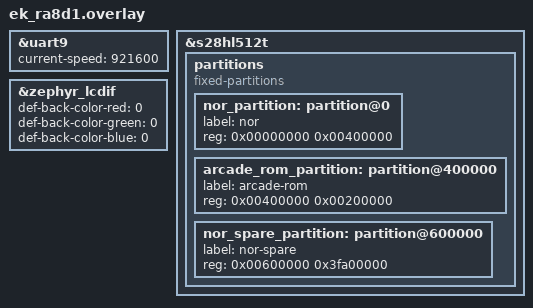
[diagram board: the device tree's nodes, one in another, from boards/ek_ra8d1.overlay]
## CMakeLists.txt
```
cmake_minimum_required(VERSION 3.20.0)
find_package(Zephyr REQUIRED HINTS $ENV{ZEPHYR_BASE})
project(ra8d1_arcade)

# emu/ is portable C99 and knows nothing about Zephyr or this board. It is
# compiled unchanged by host/Makefile for the test harnesses.
target_sources(app PRIVATE
	emu/z80.c
	emu/pacman.c
	emu/romimage.c
)

# src/ is the platform shim plus glue. platform_zephyr.c is the only file
# that knows what board this is, and it takes its facts from devicetree.
target_sources(app PRIVATE
	src/main.c
	src/platform_zephyr.c
)

# The display stage owns video.c. It builds in only once a board actually has
# a panel configured, so the two stages can land independently.
#
# Gate on a chosen zephyr,display rather than on CONFIG_DISPLAY. They are not
# the same condition: CONFIG_DISPLAY only says the display subsystem is
# compiled in, and it can be enabled on a board with no panel wired - for
# ek_ra8d1 the panel arrives with SHIELD=rtkmipilcdb00000be, not with the
# board. Gating on the Kconfig symbol makes a shieldless build fail at
# video.c's BUILD_ASSERT instead of quietly building headless.
#
# ARCADE_HAS_DISPLAY carries the same condition into C. main.c uses that
# rather than testing devicetree itself, so it keeps its rule of including no
# Zephyr headers.
dt_chosen(arcade_display_node PROPERTY "zephyr,display")
if(DEFINED arcade_display_node)
	target_sources(app PRIVATE src/video.c)
	target_compile_definitions(app PRIVATE ARCADE_HAS_DISPLAY)
endif()

target_include_directories(app PRIVATE src emu)
```

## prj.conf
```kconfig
# Native Z80 arcade emulator - board-neutral configuration.
#
# Everything here is true of the app on any Zephyr board. Board-specific
# symbols live in boards/<board>.conf, which Zephyr merges on top of this
# file. If you find yourself adding a symbol here whose name contains a
# vendor or a part number, it belongs in the board file instead.

CONFIG_PRINTK=y
CONFIG_BOOT_BANNER=n
CONFIG_MAIN_STACK_SIZE=8192

# The ROM image lives in a flash partition labelled "arcade-rom", declared by
# the board overlay. Which flash, and where, is the board's business.
CONFIG_FLASH=y

# Display output. The app runs headless without this - src/main.c only
# references video.h under CONFIG_DISPLAY - so the display stage can be
# built and landed independently of the emulator.
CONFIG_DISPLAY=y

# The emulator state is ~118 KB of .bss and we want it in internal SRAM, not
# SDRAM: the Z80's whole address space is 20 KB and keeping it on-chip is the
# single biggest win available to the interpreter.
CONFIG_SPEED_OPTIMIZATIONS=y
CONFIG_CRC=y
```

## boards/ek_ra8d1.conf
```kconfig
# EK-RA8D1 specific Kconfig for the arcade app.
#
# Merged on top of prj.conf (Zephyr appends prj.conf, then socs/, then
# boards/ - see cmake/modules/configuration_files.cmake). Only symbols that
# are true of THIS board belong here; anything the app needs on every board
# belongs in prj.conf.

# SDRAM controller. The board DTS marks &sdram okay but the memc driver class
# still has to be enabled, and on this board nothing enables it for us. Other
# boards do: stm32f746g_disco's Kconfig.defconfig has
# "config MEMC / default y if STM32_LTDC", because its display controller
# needs it. That is the board doing its own job, which is why this line is
# here rather than in prj.conf.
CONFIG_MEMC=y

# MIPI-DSI host and the GLCDC. Both are `default y` on their devicetree
# dependency once SHIELD=rtkmipilcdb00000be is applied, so these are
# belt-and-braces rather than load-bearing.
CONFIG_MIPI_DSI=y
CONFIG_RENESAS_RA_GLCDC=y

# One GLCDC framebuffer rather than the default two.
#
# For this app it is purely a memory saving: every hazard in the two-buffer
# path lives inside ra_display_write(), and src/video.c never calls it - it
# drives the GLCDC through FSP directly. At the default of 2 we would just
# reserve a second 819,840-byte buffer in SDRAM that nothing ever touches.
#
# Do NOT set this to 0. At 0 the driver's framebuffer becomes a zero-length
# array while display_get_framebuffer() still returns a non-NULL pointer into
# it, and plat_video_init() memsets 819,840 bytes through that pointer.
CONFIG_RENESAS_RA_GLCDC_FB_NUM=1

# The GT911 touch controller on the MIPI shield shares the DSI reset line
# with the panel, so the panel does not come up without I2C available.
CONFIG_I2C=y

# D-cache is a 3.8x swing on SDRAM reads on this board (123 vs 32 MiB/s), and
# the GLCDC scans out of SDRAM as a bus master that does not see the cache,
# so cache maintenance has to be available for video.c to flush against.
CONFIG_ICACHE=y
CONFIG_DCACHE=y
CONFIG_CACHE_MANAGEMENT=y
```

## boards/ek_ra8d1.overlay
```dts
/*
 * EK-RA8D1 wiring for the arcade app.
 *
 * Everything in this file is specific to this board: node labels like
 * `uart9`, `s28hl512t` and `zephyr_lcdif` exist on the EK-RA8D1 and nowhere
 * else. Porting to another Zephyr board means writing a sibling file here,
 * `boards/<board>.overlay`, and changing no source.
 *
 * Note there is deliberately no `app.overlay`. Zephyr picks the application
 * devicetree overlay by a fallback chain, not a merge (see
 * cmake/modules/configuration_files.cmake): once `boards/<board>.overlay`
 * exists it is used and `app.overlay` is never read. Keeping both would mean
 * the second one silently does nothing. Genuinely board-neutral devicetree,
 * if we ever have any, belongs in a `.dtsi` included from each board file.
 *
 * Kconfig is the other way round: `prj.conf` and `boards/<board>.conf` are
 * merged, so the board-specific Kconfig lives in the sibling `.conf`.
 */

/* Console at 921600 rather than 115200. Pushing a ROM image is only ~25 KB
 * for Pac-Man so the baud hardly matters here, but the rvlinux app on this
 * board already runs its console at this rate and the J-Link OB VCOM handles
 * it, so one terminal setting works for both. */
&uart9 {
	current-speed = <921600>;
};

/*
 * Carve a ROM slot out of the octo-SPI NOR.
 *
 * The board DTS declares a single "nor" partition covering all 64 MB. Split
 * it so the arcade ROM has a named home the app can find by label, instead
 * of a hardcoded 0x400000 in C.
 *
 * The layout below matches what is already on this part: 0x0-0x1FFFF is the
 * CIRCUITPY filesystem and 0x2000 is the OSPI driver's autocalibration
 * sector, and the emulated-Linux image sits from 0x40000 and runs to a few
 * MB. The arcade slot starts at 4 MB, clear of all of it, and is 2 MB, which
 * is ample: a full Pac-Man image is ~25 KB.
 */
&s28hl512t {
	/delete-node/ partitions;

	partitions {
		compatible = "fixed-partitions";
		#address-cells = <1>;
		#size-cells = <1>;

		/* Everything the other apps on this board already use. */
		nor_partition: partition@0 {
			label = "nor";
			reg = <0x00000000 0x00400000>;
		};

		arcade_rom_partition: partition@400000 {
			label = "arcade-rom";
			reg = <0x00400000 0x00200000>;
		};

		/* The rest of the 64 MB part, unclaimed. */
		nor_spare_partition: partition@600000 {
			label = "nor-spare";
			reg = <0x00600000 0x3fa00000>;
		};
	};
};

/*
 * Black the letterbox.
 *
 * The arcade raster is 224x288 and the panel is 480x854, so the scaled image
 * never fills the screen and the GLCDC paints the surround with its default
 * background colour. The driver defaults every channel to 255
 * (display_renesas_ra.h, DT_INST_PROP_OR(n, def_back_color_*, 255)), so
 * without this the border comes up white.
 *
 * `zephyr_lcdif` is labelled in ek_ra8d1.dts itself, not in the shield, so
 * this is safe to apply to a headless build too: the node is simply disabled
 * and these properties go nowhere.
 */
&zephyr_lcdif {
	def-back-color-red = <0>;
	def-back-color-green = <0>;
	def-back-color-blue = <0>;
};
```

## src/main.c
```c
/*
 * Namco Pac-Man arcade hardware, emulated natively on a Cortex-M85.
 *
 * This runs directly on the MCU. It is deliberately NOT hosted inside the
 * emulated RISC-V Linux that also lives on the EK-RA8D1: nesting an M85
 * emulating a RISC-V emulating a Z80 compounds to well over a thousand host
 * cycles per Z80 instruction, roughly ten times too slow for Pac-Man's
 * 3.072 MHz. Emulating the Z80 directly costs tens of cycles.
 *
 * Layering, which is the point of how this file is written:
 *
 *   emu/       portable C99, no Zephyr, no board. Compiles on the Mac for
 *              the test harnesses and on the target unchanged.
 *   src/platform.h, video.h
 *              the thin shim: ROM storage, timing, input, framebuffer.
 *   src/platform_zephyr.c, video.c
 *              the only files that know the board, and they take their facts
 *              from devicetree rather than from constants.
 *   src/main.c this file. Glue only: no addresses, no panel size, no flash
 *              offsets, no driver includes.
 *
 * ROMs: none are shipped. Push an image built by tools/mkromimage.py (your
 * own dump) or tools/mktestrom.py (synthetic, no arcade ROM involved) with
 * tools/pushrom.py. It persists across resets and app reflashes.
 */

/* No Zephyr headers here on purpose: this file is glue, and everything it
 * needs from the system comes through platform.h and video.h. That keeps it
 * compilable against any implementation of the shim. */
#include <stdbool.h>
#include <stddef.h>
#include <stdint.h>
#include <string.h>

#include "pacman.h"
#include "romimage.h"
#include "platform.h"

/* The display stage owns video.h/video.c. Until the board has a panel - a
 * chosen zephyr,display, which CMakeLists turns into ARCADE_HAS_DISPLAY -
 * this app runs headless and never references it, so the two stages can land
 * independently. */
#if defined(ARCADE_HAS_DISPLAY)
#include "video.h"
#endif

/* ------------------------------------------------------------------- state */

/* ~118 KB. Lives in .bss, i.e. internal SRAM: the Z80's whole address space
 * is 20 KB and the decoded graphics are 32 KB, so the emulator's hot working
 * set stays on-chip and never touches external memory. That is the single
 * biggest performance decision in the project. */
static pacman_t machine;

/* ------------------------------------------------------------- console fmt */

static void us(const char *s)
{
	plat_puts(s);
}

static void udec(uint32_t v)
{
	char b[12];
	int n = 0;

	if (v == 0) {
		plat_putc('0');
		return;
	}
	while (v) {
		b[n++] = (char) ('0' + v % 10);
		v /= 10;
	}
	while (n--) {
		plat_putc(b[n]);
	}
}

/* Fixed-point decimal with two places, for rates and multiples. */
static void udec2(uint32_t whole, uint32_t hundredths)
{
	udec(whole);
	plat_putc('.');
	plat_putc((char) ('0' + (hundredths / 10) % 10));
	plat_putc((char) ('0' + hundredths % 10));
}

/* ----------------------------------------------------------------- rom load */

static bool rom_present(romimg_t *img)
{
	size_t slot;
	const uint8_t *base = plat_rom_base(&slot);

	if (base == NULL) {
		us("rom: no ROM storage on this platform\r\n");
		return false;
	}

	romimg_err_t e = romimg_parse(base, slot, true, img);

	if (e == ROMIMG_OK) {
		e = romimg_check_pacman(img);
	}
	if (e != ROMIMG_OK) {
		us("rom: ");
		us(romimg_strerror(e));
		us("\r\n");
		return false;
	}

	us("rom: ok, ");
	udec(img->total_len);
	us(" bytes");
	if (img->flags & ROMIMG_FLAG_SYNTHETIC) {
		us(" (synthetic test image)");
	}
	us("\r\n");
	return true;
}

/*
 * Receive a ROM image over the console and hand it to the platform.
 *
 * The container carries its own length and CRC, so the wire protocol is just
 * 'S', a 4-byte little-endian length, then the bytes. Erase granularity,
 * write-block size and the hold-back of the header block are all the
 * platform's problem, not this function's.
 */
static int rom_receive(void)
{
	uint32_t len = 0;
	int c;

	us("\r\nLOADER: send 'S' then <len:4 LE> then the image\r\n");

	do {
		c = plat_getc_timeout(3600u * 1000u);
		if (c < 0) {
			us("LOADER: timeout\r\n");
			return -1;
		}
	} while (c != 'S');

	for (int i = 0; i < 4; i++) {
		c = plat_getc_timeout(5000u);
		if (c < 0) {
			return -1;
		}
		len |= (uint32_t) c << (8 * i);
	}

	us("LOADER: len=");
	udec(len);
	us(", erasing\r\n");

	if (plat_rom_write_begin(len) != 0) {
		us("LOADER: cannot open ROM slot\r\n");
		return -1;
	}

	/* The erase is long enough that anything sent meanwhile is already lost
	 * in the FIFO. Drain, then say explicitly when ready. */
	while (plat_getc() >= 0) {
		/* drain */
	}
	us("\r\n<RDY>\r\n");

	for (uint32_t off = 0; off < len; off++) {
		uint8_t byte;

		c = plat_getc_timeout(10000u);
		if (c < 0) {
			us("LOADER: rx timeout at ");
			udec(off);
			us("\r\n");
			return -1;
		}
		byte = (uint8_t) c;

		if (plat_rom_write(&byte, 1) != 0) {
			us("LOADER: write failed at ");
			udec(off);
			us("\r\n");
			return -1;
		}
		if ((off & 0xFFF) == 0) {
			plat_putc('.');
		}
	}

	if (plat_rom_write_end() != 0) {
		us("\r\nLOADER: commit failed\r\n");
		return -1;
	}

	us("\r\nLOADER: done\r\n");
	return 0;
}

/* --------------------------------------------------------------- benchmark */

/*
 * How much faster than real time can this board run the machine?
 *
 * CPU and render only. The cost of getting pixels onto the panel is measured
 * by the video layer, which is where the scaling strategy lives; see
 * notes/02-video.md. Duplicating a blit here would only produce a second,
 * stale number for the same thing.
 */
static void benchmark(void)
{
	const int warm = 30;
	const int n = 300;

	machine.watchdog_enable = false;    /* a reset mid-run skews the counts */

	for (int i = 0; i < warm; i++) {
		pacman_run_frame(&machine);
	}

	uint64_t i0 = machine.instrs;
	unsigned long c0 = machine.cpu.cyc;

	uint64_t t0 = plat_now_us();

	for (int i = 0; i < n; i++) {
		pacman_run_frame(&machine);
	}
	uint64_t t_full = plat_now_us() - t0;

	uint64_t instrs = machine.instrs - i0;
	uint32_t tstates = (uint32_t) (machine.cpu.cyc - c0);

	t0 = plat_now_us();
	for (int i = 0; i < n; i++) {
		pacman_render(&machine);
	}
	uint64_t t_render = plat_now_us() - t0;

	uint64_t t_cpu = (t_full > t_render) ? (t_full - t_render) : 1;

	us("\r\n--- benchmark over ");
	udec(n);
	us(" frames ---\r\n");

	us("z80 instructions   ");
	udec((uint32_t) instrs);
	us("  (");
	udec((uint32_t) (instrs / n));
	us(" per frame)\r\n");

	us("t-states per instr ");
	udec2(tstates / (uint32_t) instrs,
	      (uint32_t) ((uint64_t) tstates * 100 / instrs) % 100);
	us("\r\n");

	us("cpu emulation      ");
	udec((uint32_t) (t_cpu / n));
	us(" us/frame, ");
	udec((uint32_t) (instrs * 1000000u / t_cpu / 1000u));
	us(" K z80-instr/s\r\n");

	us("render 224x288     ");
	udec((uint32_t) (t_render / n));
	us(" us/frame\r\n");

	uint32_t us_frame = (uint32_t) (t_full / n);
	uint32_t us_budget = 1000000u / 61u;

	us("emulation total    ");
	udec(us_frame);
	us(" us of a ");
	udec(us_budget);
	us(" us frame budget\r\n");

	if (us_frame) {
		uint32_t x100 = us_budget * 100u / us_frame;

		us("real-time multiple ");
		udec2(x100 / 100, x100 % 100);
		us("x  (emulation only, display not included)\r\n");
	}

	machine.watchdog_enable = true;
	pacman_reset(&machine);
}

/* -------------------------------------------------------------------- main */

/* Map the platform's abstract buttons onto this machine's cabinet. Which
 * physical control produces which bit is the platform's business; which
 * cabinet input it drives is this machine's. */
static void apply_input(uint32_t btns)
{
	static const struct {
		uint32_t bit;
		pacman_btn_t btn;
	} map[] = {
		{ PLAT_BTN_UP,     PACMAN_BTN_UP },
		{ PLAT_BTN_DOWN,   PACMAN_BTN_DOWN },
		{ PLAT_BTN_LEFT,   PACMAN_BTN_LEFT },
		{ PLAT_BTN_RIGHT,  PACMAN_BTN_RIGHT },
		{ PLAT_BTN_COIN,   PACMAN_BTN_COIN1 },
		{ PLAT_BTN_START1, PACMAN_BTN_START1 },
		{ PLAT_BTN_START2, PACMAN_BTN_START2 },
	};

	for (unsigned i = 0; i < sizeof(map) / sizeof(map[0]); i++) {
		pacman_set_input(&machine, map[i].btn,
				 (btns & map[i].bit) != 0);
	}
}

int main(void)
{
	us("\r\n\r\nra8d1-arcade: pac-man, native on cortex-m85\r\n");

	romimg_t img;

	if (!rom_present(&img)) {
		us("\r\nNo usable ROM image in flash.\r\n");
		us("Build one with tools/mktestrom.py (synthetic, no arcade\r\n");
		us("ROM needed) or tools/mkromimage.py (your own dump), then\r\n");
		us("push it with tools/pushrom.py.\r\n");

		if (rom_receive() != 0 || !rom_present(&img)) {
			us("no valid image; halting\r\n");
			return 0;
		}
	}

	if (!pacman_load(&machine, img.cpu, img.gfx, img.prom)) {
		us("pacman_load failed\r\n");
		return 0;
	}
	us("machine loaded, state ");
	udec((uint32_t) sizeof(machine) / 1024);
	us(" KB in internal SRAM\r\n");

	/*
	 * Draw straight into the platform's framebuffer when there is one.
	 * pacman_render() writes PACMAN_W x PACMAN_H bytes of palette index at
	 * whatever stride it is given, so this costs nothing and saves a 64 KB
	 * copy per frame. Without a display the machine keeps its own buffer
	 * and everything still runs.
	 */
	bool have_display = false;

#if defined(ARCADE_HAS_DISPLAY)
	if (plat_video_init(PACMAN_W, PACMAN_H) == 0) {
		uint32_t pal[32];

		pacman_set_surface(&machine, plat_get_framebuffer(),
				   plat_fb_stride());
		pacman_palette_rgb888(&machine, pal);
		plat_set_palette(pal, 0, 32);
		have_display = true;

		us("display ");
		udec(plat_fb_width() * plat_scale());
		plat_putc('x');
		udec(plat_fb_height() * plat_scale());
		us(" at ");
		udec(plat_scale());
		us("x scale\r\n");
	} else {
		us("display init failed; running headless\r\n");
	}
#else
	us("no display configured; running headless\r\n");
#endif

	benchmark();

	us("\r\nfree-running at 60.6 Hz\r\n");

	const uint64_t frame_us = 1000000u / 61u;
	uint64_t next = plat_now_us();

	for (;;) {
		apply_input(plat_poll_input());

		if (have_display) {
#if defined(ARCADE_HAS_DISPLAY)
			plat_wait_vsync();
#endif
		}

		pacman_run_frame(&machine);

		if (have_display) {
#if defined(ARCADE_HAS_DISPLAY)
			plat_present();
#endif
		}

		next += frame_us;
		plat_sleep_until_us(next);

		if (machine.frame % 303 == 0) {
			us("frame ");
			udec(machine.frame);
			us("\r\n");
		}
	}

	return 0;
}
```

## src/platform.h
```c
/*
 * platform.h - everything board-specific that is not video.
 *
 * Portable by construction: stdint/stdbool/stddef only, no Zephyr, no FSP, no
 * devicetree, no board constants. The app and the machine layer include this
 * to reach the hardware; the implementation is the only file allowed to know
 * what board it is on.
 *
 * Video deliberately lives in its own header, video.h, because the display
 * contract is larger and has its own lifecycle. The split is:
 *
 *   video.h     framebuffer, palette, scaling, vsync, present
 *   platform.h  ROM storage, wall clock, input
 *
 * A port to another Zephyr board should need a new implementation file and a
 * devicetree, and no change above this line.
 */
#ifndef ARCADE_PLATFORM_H_
#define ARCADE_PLATFORM_H_

#include <stdbool.h>
#include <stddef.h>
#include <stdint.h>

/* --------------------------------------------------------------- rom store */

/*
 * The ROM image, as a directly readable pointer.
 *
 * Platforms with memory-mapped flash return a pointer into that window and
 * the image is parsed and decoded in place, with no copy. Platforms without
 * it are free to read the image into RAM and return that instead; callers
 * cannot tell the difference and must not assume either.
 *
 * Returns NULL if the platform has no ROM storage at all. `size` is set to
 * the number of bytes readable from the returned pointer, which is the size
 * of the slot, not of the image; the container header carries the real
 * length.
 */
const uint8_t *plat_rom_base(size_t *size);

/*
 * Commit `len` bytes to the ROM slot, replacing whatever was there.
 *
 * Split into begin/write/end because erase granularity, write-block size and
 * alignment are all platform properties: some parts refuse writes that are
 * not whole aligned blocks. The implementation buffers as needed, so callers
 * may pass any chunk size.
 *
 * Returns 0 or a negative errno. Not all platforms implement this; -ENOTSUP
 * from plat_rom_write_begin() means "no writable ROM slot here".
 */
int plat_rom_write_begin(size_t len);
int plat_rom_write(const uint8_t *data, size_t len);
int plat_rom_write_end(void);

/* ------------------------------------------------------------------ timing */

/* Monotonic microseconds since boot. Must be cheap: the frame loop and the
 * benchmark both call it. */
uint64_t plat_now_us(void);

/* Busy-wait until plat_now_us() reaches `deadline_us`. */
void plat_sleep_until_us(uint64_t deadline_us);

/* ------------------------------------------------------------------- input */

/*
 * Abstract cabinet controls, active high (pressed = 1). The machine layer
 * maps these onto whatever its board's input ports look like; the platform
 * maps them from whatever the hardware has - GPIO, USB HID, a UART key, or
 * nothing at all.
 */
enum {
	PLAT_BTN_UP     = 1u << 0,
	PLAT_BTN_DOWN   = 1u << 1,
	PLAT_BTN_LEFT   = 1u << 2,
	PLAT_BTN_RIGHT  = 1u << 3,
	PLAT_BTN_FIRE   = 1u << 4,
	PLAT_BTN_COIN   = 1u << 5,
	PLAT_BTN_START1 = 1u << 6,
	PLAT_BTN_START2 = 1u << 7,
};

/* Current button state as a bitmask of PLAT_BTN_*. Returns 0 on a platform
 * with no input wired up, which is a valid configuration: the machine just
 * sees an idle cabinet. */
uint32_t plat_poll_input(void);

/* ----------------------------------------------------------------- console */

/* Byte-level console, used for diagnostics and the ROM loader. Kept here so
 * the app does not include a UART driver directly. */
void plat_putc(char c);
void plat_puts(const char *s);

/* Returns the next byte, or -1 if none is available. */
int plat_getc(void);

/* Blocks up to `timeout_ms` for a byte; -1 on timeout. */
int plat_getc_timeout(uint32_t timeout_ms);

#endif /* ARCADE_PLATFORM_H_ */
```

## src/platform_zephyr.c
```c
/*
 * platform_zephyr.c - the Zephyr implementation of src/platform.h.
 *
 * This is the ONLY file in the project that is allowed to know what board it
 * is running on, and even here the board facts come from devicetree rather
 * than from constants:
 *
 *   console        DT_CHOSEN(zephyr_console)
 *   ROM slot       the "arcade-rom" fixed-partition: device, offset and size
 *   XIP window     DT_REG_ADDR of the flash node the partition lives on
 *   erase/write    the flash driver's own page layout and write-block size
 *
 * Porting to another Zephyr board should mean writing a devicetree overlay
 * that declares an "arcade-rom" partition, not editing this file. If the
 * board's flash is not memory-mapped, plat_rom_base() falls back to reading
 * the image into RAM and callers cannot tell.
 */

#include <zephyr/kernel.h>
#include <zephyr/device.h>
#include <zephyr/devicetree.h>
#include <zephyr/drivers/uart.h>
#include <zephyr/drivers/flash.h>
#include <zephyr/storage/flash_map.h>
#include <zephyr/cache.h>
#include <zephyr/sys/util.h>
#include <string.h>
#include <errno.h>

#include "platform.h"

/* ------------------------------------------------------------------- board */

#define ROM_PARTITION       arcade_rom_partition

/* DT_MTD_FROM_FIXED_PARTITION walks partition -> partitions -> flash node,
 * so the device, its XIP window and the slot bounds all come from the same
 * devicetree entry and cannot drift apart. */
#define ROM_FLASH_NODE      DT_MTD_FROM_FIXED_PARTITION(DT_NODELABEL(ROM_PARTITION))
#define ROM_FLASH_DEV       DEVICE_DT_GET(ROM_FLASH_NODE)
#define ROM_OFFSET          DT_REG_ADDR(DT_NODELABEL(ROM_PARTITION))
#define ROM_SIZE            DT_REG_SIZE(DT_NODELABEL(ROM_PARTITION))

/* The flash node's own reg gives the memory-mapped (XIP) base and the part
 * size. On this board that is 0x90000000 and 64 MB, but taking it from the
 * node means a different part or a different chip select needs no edit. */
#define FLASH_XIP_BASE      DT_REG_ADDR(ROM_FLASH_NODE)

/* Largest erase block the part advertises, used to round the erase up. */
#define ROM_ERASE_SZ        (256U * 1024U)

/* Small flash_write() calls fail on this NOR, so writes are buffered into
 * whole aligned blocks. See ra8d1-linux/ra8d-bringup.md. */
#define ROM_WRITE_BLK       4096U

/*
 * Devicetree sanity, checked at build time so a bad overlay is a compile
 * error rather than a confusing runtime failure. These are invariants, not
 * addresses: asserting specific values here would just move the board
 * constants back into C, which is what the devicetree is for.
 */
BUILD_ASSERT(ROM_OFFSET % ROM_ERASE_SZ == 0,
	     "arcade-rom partition must start on an erase-block boundary");
BUILD_ASSERT(ROM_SIZE % ROM_ERASE_SZ == 0,
	     "arcade-rom partition must be a whole number of erase blocks");
BUILD_ASSERT(ROM_SIZE >= 64 * 1024,
	     "arcade-rom partition is too small to hold a ROM image");
BUILD_ASSERT(ROM_ERASE_SZ % ROM_WRITE_BLK == 0,
	     "write block must divide the erase block");

static const struct device *const console_dev =
	DEVICE_DT_GET(DT_CHOSEN(zephyr_console));
static const struct device *const rom_flash = ROM_FLASH_DEV;

/* ----------------------------------------------------------------- console */

void plat_putc(char c)
{
	uart_poll_out(console_dev, c);
}

void plat_puts(const char *s)
{
	while (*s) {
		uart_poll_out(console_dev, *s++);
	}
}

int plat_getc(void)
{
	unsigned char c;

	return (uart_poll_in(console_dev, &c) == 0) ? (int) c : -1;
}

int plat_getc_timeout(uint32_t timeout_ms)
{
	int64_t end = k_uptime_get() + timeout_ms;
	int c;

	do {
		c = plat_getc();
		if (c >= 0) {
			return c;
		}
		k_busy_wait(50);
	} while (k_uptime_get() < end);

	return -1;
}

/* ------------------------------------------------------------------ timing */

uint64_t plat_now_us(void)
{
	return (uint64_t) k_ticks_to_us_floor64(k_uptime_ticks());
}

void plat_sleep_until_us(uint64_t deadline_us)
{
	for (;;) {
		uint64_t now = plat_now_us();

		if (now >= deadline_us) {
			return;
		}
		/* Long waits go to the scheduler; the last stretch spins so the
		 * frame does not overshoot by a whole tick. */
		if (deadline_us - now > 2000) {
			k_sleep(K_USEC(deadline_us - now - 1000));
		} else {
			k_busy_wait(20);
		}
	}
}

/* ------------------------------------------------------------------- input */

/*
 * Nothing is wired up yet. The board's two user buttons are the obvious
 * first move, and USB HID after that; both belong here rather than in the
 * machine layer. Returning 0 is a valid configuration - the machine simply
 * sees an idle cabinet.
 */
uint32_t plat_poll_input(void)
{
	return 0;
}

/* ---------------------------------------------------------------- rom store */

const uint8_t *plat_rom_base(size_t *size)
{
	if (size) {
		*size = ROM_SIZE;
	}

	/* This part is memory-mapped, so hand back a pointer into the XIP
	 * window and let the emulator decode in place. The window is cacheable,
	 * so drop any lines that predate a write we may have just done. */
	const uint8_t *p = (const uint8_t *) (FLASH_XIP_BASE + ROM_OFFSET);

	sys_cache_data_invd_range((void *) p, ROM_SIZE);
	return p;
}

/* Write state. The block buffer exists because the NOR rejects partial
 * writes, and callers should not have to care. */
static uint8_t wr_blk[ROM_WRITE_BLK];
static uint8_t wr_first[ROM_WRITE_BLK];
static size_t wr_fill;      /* bytes buffered in wr_blk */
static size_t wr_off;       /* bytes committed so far */
static size_t wr_total;
static bool wr_have_first;
static bool wr_active;

int plat_rom_write_begin(size_t len)
{
	if (!device_is_ready(rom_flash)) {
		return -ENODEV;
	}
	if (len == 0 || len > ROM_SIZE) {
		return -EINVAL;
	}

	size_t need = ROUND_UP(len, ROM_ERASE_SZ);

	if (flash_erase(rom_flash, ROM_OFFSET, need) != 0) {
		return -EIO;
	}

	wr_fill = 0;
	wr_off = 0;
	wr_total = len;
	wr_have_first = false;
	wr_active = true;
	return 0;
}

/* Commit one full block. The very first block holds the container magic and
 * is held back until the end, so a transfer that dies halfway never leaves
 * something that parses as a valid image. */
static int commit_block(void)
{
	int rc = 0;

	if (wr_off == 0) {
		memcpy(wr_first, wr_blk, ROM_WRITE_BLK);
		wr_have_first = true;
	} else {
		rc = flash_write(rom_flash, ROM_OFFSET + wr_off, wr_blk,
				 ROM_WRITE_BLK);
	}

	wr_off += ROM_WRITE_BLK;
	wr_fill = 0;
	memset(wr_blk, 0xFF, sizeof(wr_blk));
	return rc ? -EIO : 0;
}

int plat_rom_write(const uint8_t *data, size_t len)
{
	if (!wr_active) {
		return -EINVAL;
	}

	while (len) {
		size_t n = MIN(len, ROM_WRITE_BLK - wr_fill);

		memcpy(wr_blk + wr_fill, data, n);
		wr_fill += n;
		data += n;
		len -= n;

		if (wr_fill == ROM_WRITE_BLK) {
			int rc = commit_block();

			if (rc) {
				wr_active = false;
				return rc;
			}
		}
	}
	return 0;
}

int plat_rom_write_end(void)
{
	int rc = 0;

	if (!wr_active) {
		return -EINVAL;
	}

	/* Flush a partial tail, padded with erased bytes. */
	if (wr_fill) {
		memset(wr_blk + wr_fill, 0xFF, ROM_WRITE_BLK - wr_fill);
		rc = commit_block();
	}

	/* Now the magic, last. */
	if (rc == 0 && wr_have_first) {
		if (flash_write(rom_flash, ROM_OFFSET, wr_first,
				ROM_WRITE_BLK) != 0) {
			rc = -EIO;
		}
	}

	sys_cache_data_invd_range((void *) (FLASH_XIP_BASE + ROM_OFFSET),
				  ROUND_UP(wr_total, ROM_ERASE_SZ));
	wr_active = false;
	return rc;
}
```

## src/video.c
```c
/*
 * video.c - EK-RA8D1 implementation of the platform video interface.
 *
 * Everything board-specific lives below this line: the panel geometry comes
 * from devicetree, and the GLCDC is driven through FSP directly.
 *
 * The Zephyr display driver brings the GLCDC, the MIPI-DSI host and the
 * ILI9806E panel up for us. We then stop using its display_write() API
 * entirely:
 *
 *   R_GLCDC_Start        once, to begin scanout
 *   R_GLCDC_ClutUpdate   to load the palette into the hardware CLUT
 *   R_GLCDC_LayerChange  once, to retarget layer 1 at our CLUT8 sub-window
 *   R_GLCDC_BufferChange per frame, to flip
 *
 * display_write() is never called, so the k_sem_take(frame_buf_sem, K_FOREVER)
 * at display_renesas_ra.c:147 is never reached. That is the whole reason for
 * going around the Zephyr display API rather than through it.
 *
 * The GLCDC scans out of SDRAM continuously and asynchronously. Per frame we
 * make exactly one FSP call, and only to swap which buffer it reads.
 */

#include "video.h"

#include <zephyr/cache.h>
#include <zephyr/device.h>
#include <zephyr/devicetree.h>
#include <zephyr/drivers/display.h>
#include <zephyr/kernel.h>
#include <zephyr/linker/devicetree_regions.h>
#include <zephyr/logging/log.h>

#include <string.h>

#include <r_glcdc.h>

LOG_MODULE_REGISTER(video, LOG_LEVEL_INF);

#define GLCDC_NODE DT_CHOSEN(zephyr_display)
#define SDRAM_NODE DT_NODELABEL(sdram1)

/* Board facts, from devicetree rather than constants. */
#define PANEL_W DT_PROP(GLCDC_NODE, width)
#define PANEL_H DT_PROP(GLCDC_NODE, height)

BUILD_ASSERT(DT_NODE_HAS_COMPAT(GLCDC_NODE, renesas_ra_glcdc),
	     "chosen zephyr,display must be the GLCDC (build with SHIELD=rtkmipilcdb00000be)");

/*
 * The GLCDC requires the framebuffer base address and the byte stride to both
 * be multiples of 64 (r_glcdc.c:26, 1003-1008).
 */
#define GLCDC_ALIGN 64
#define ALIGN64(x)  (((x) + (GLCDC_ALIGN - 1)) & ~(GLCDC_ALIGN - 1))

/*
 * Worst case sizing for the two scanout buffers: a full-panel-width layer with
 * a 64-byte-aligned stride. At 480x854 CLUT8 that is 512 * 854 = 437,248 bytes
 * each. The real layer is smaller; this is just the static reservation, and
 * 64 MB of SDRAM makes the slack irrelevant.
 */
#define SCANOUT_MAX_BYTES (ALIGN64(PANEL_W) * PANEL_H)

/* Likewise for the machine's own 8bpp surface. */
#define SRC_MAX_BYTES (ALIGN64(PANEL_W) * PANEL_H)

Z_GENERIC_SECTION(LINKER_DT_NODE_REGION_NAME(SDRAM_NODE))
static uint8_t __aligned(GLCDC_ALIGN) scanout[2][SCANOUT_MAX_BYTES];

Z_GENERIC_SECTION(LINKER_DT_NODE_REGION_NAME(SDRAM_NODE))
static uint8_t __aligned(GLCDC_ALIGN) surface[SRC_MAX_BYTES];

/*
 * i -> i,i as a little-endian halfword. Doubling a pixel becomes one table
 * read and one store instead of a shift and two stores.
 */
static uint16_t dup2[256];

static struct {
	glcdc_instance_ctrl_t *glcdc;
	unsigned src_w, src_h;
	unsigned src_stride;
	unsigned scale;
	unsigned dst_w, dst_h;
	unsigned dst_stride;
	uint8_t back;
	uint32_t frames;
	bool ready;
} vid;

/*
 * struct display_ra_data is private to the Zephyr driver, but its first member
 * is the FSP control block:
 *
 *   struct display_ra_data {
 *           glcdc_instance_ctrl_t display_ctrl;    <- offset 0
 *           display_cfg_t display_fsp_cfg;
 *           ...
 *   };
 *
 * so dev->data is a valid glcdc_instance_ctrl_t *. plat_video_init() checks
 * the state field straight afterwards, which fails loudly if that struct is
 * ever reordered upstream.
 */
static glcdc_instance_ctrl_t *glcdc_ctrl_of(const struct device *dev)
{
	return (glcdc_instance_ctrl_t *)dev->data;
}

/* The GLCDC clears PVEN once the shadow registers have been latched at vsync. */
static inline bool flip_pending(void)
{
	return R_GLCDC->GR[DISPLAY_FRAME_LAYER_1].VEN_b.PVEN != 0U;
}

/* --- scaling ------------------------------------------------------------ */

/*
 * 2x is the case that matters (224x288 on a 480x854 panel), so it gets a
 * dedicated path: two source pixels are table-doubled into halfwords, packed
 * into one 32-bit store, and the second output row is a memcpy of the first.
 */
static void blit_2x(const uint8_t *src, uint8_t *dst)
{
	for (unsigned y = 0; y < vid.src_h; y++) {
		const uint8_t *s = src + (size_t)y * vid.src_stride;
		uint32_t *d = (uint32_t *)dst;

		for (unsigned x = 0; x < vid.src_w; x += 2) {
			*d++ = (uint32_t)dup2[s[x]] | ((uint32_t)dup2[s[x + 1]] << 16);
		}

		memcpy(dst + vid.dst_stride, dst, vid.dst_w);
		dst += 2 * vid.dst_stride;
	}
}

/* Any integer scale, including 1x. Correct rather than fast. */
static void blit_nx(const uint8_t *src, uint8_t *dst)
{
	const unsigned n = vid.scale;

	for (unsigned y = 0; y < vid.src_h; y++) {
		const uint8_t *s = src + (size_t)y * vid.src_stride;
		uint8_t *d = dst;

		for (unsigned x = 0; x < vid.src_w; x++) {
			memset(d, s[x], n);
			d += n;
		}

		for (unsigned r = 1; r < n; r++) {
			memcpy(dst + (size_t)r * vid.dst_stride, dst, vid.dst_w);
		}

		dst += (size_t)n * vid.dst_stride;
	}
}

/* --- interface ---------------------------------------------------------- */

int plat_video_init(unsigned src_w, unsigned src_h)
{
	display_runtime_cfg_t rt;
	const struct device *dev;
	fsp_err_t err;

	if (src_w == 0 || src_h == 0) {
		return -EINVAL;
	}

	/* Largest integer scale that fits both axes. */
	unsigned scale = MIN(PANEL_W / src_w, PANEL_H / src_h);

	if (scale == 0) {
		LOG_ERR("%ux%u does not fit a %ux%u panel even at 1:1", src_w, src_h,
			(unsigned)PANEL_W, (unsigned)PANEL_H);
		return -ERANGE;
	}

	vid.src_w = src_w;
	vid.src_h = src_h;
	vid.src_stride = ALIGN64(src_w);
	vid.scale = scale;
	vid.dst_w = src_w * scale;
	vid.dst_h = src_h * scale;
	vid.dst_stride = ALIGN64(vid.dst_w);

	if ((size_t)vid.src_stride * src_h > sizeof(surface) ||
	    (size_t)vid.dst_stride * vid.dst_h > sizeof(scanout[0])) {
		return -ENOMEM;
	}

	/* GLCDC rejects an odd layer width (r_glcdc.c:1129). */
	if (vid.dst_w % 2) {
		LOG_ERR("scaled width %u is odd; GLCDC needs it even", vid.dst_w);
		return -EINVAL;
	}

	for (unsigned i = 0; i < 256; i++) {
		dup2[i] = (uint16_t)(i | (i << 8));
	}

	dev = DEVICE_DT_GET(GLCDC_NODE);
	if (!device_is_ready(dev)) {
		LOG_ERR("GLCDC device not ready");
		return -ENODEV;
	}

	vid.glcdc = glcdc_ctrl_of(dev);
	if (vid.glcdc->state != DISPLAY_STATE_OPENED) {
		LOG_ERR("GLCDC state %d, expected OPENED(1) - dev->data cast is wrong",
			(int)vid.glcdc->state);
		return -EINVAL;
	}

	/*
	 * The driver's own framebuffer (CONFIG_RENESAS_RA_GLCDC_FB_NUM=1) is
	 * what the hardware scans for the frame or two before our LayerChange
	 * is latched. Black it out so boot does not flash garbage.
	 */
	uint8_t *dt_fb = (uint8_t *)display_get_framebuffer(dev);
	const size_t dt_fb_len = (size_t)PANEL_W * PANEL_H * 2;

	if (dt_fb != NULL) {
		memset(dt_fb, 0, dt_fb_len);
		sys_cache_data_flush_range(dt_fb, dt_fb_len);
	}

	memset(surface, 0, sizeof(surface));
	memset(scanout, 0, sizeof(scanout));
	sys_cache_data_flush_range(scanout, sizeof(scanout));

	/* Scanout has to be running before LayerChange has a vsync to latch on. */
	err = R_GLCDC_Start((display_ctrl_t *)vid.glcdc);
	if (err != FSP_SUCCESS) {
		LOG_ERR("R_GLCDC_Start failed (%d)", (int)err);
		return -EIO;
	}

	/*
	 * Retarget layer 1 at our CLUT8 buffer, sized and positioned so the
	 * hardware reads only the active area and paints the rest with the
	 * background colour. Set def-back-color-{red,green,blue} = 0 in the
	 * devicetree or that border comes out white.
	 */
	rt.input = (display_input_cfg_t){
		.p_base = (uint32_t *)scanout[0],
		.hsize = (uint16_t)vid.dst_w,
		.vsize = (uint16_t)vid.dst_h,
		.hstride = vid.dst_stride, /* in pixels, despite the FSP comment */
		.format = DISPLAY_IN_FORMAT_CLUT8,
		.line_descending_enable = false,
		.lines_repeat_enable = false,
		.lines_repeat_times = 0,
	};
	rt.layer = (display_layer_t){
		.coordinate = {.x = (int16_t)((PANEL_W - vid.dst_w) / 2),
			       .y = (int16_t)((PANEL_H - vid.dst_h) / 2)},
		.bg_color = {.byte = {.a = 0xFF, .r = 0, .g = 0, .b = 0}},
		.fade_control = DISPLAY_FADE_CONTROL_NONE,
		.fade_speed = 0,
	};

	do {
		err = R_GLCDC_LayerChange((display_ctrl_t *)vid.glcdc, &rt,
					  DISPLAY_FRAME_LAYER_1);
		if (err == FSP_ERR_INVALID_UPDATE_TIMING) {
			k_msleep(1);
		}
	} while (err == FSP_ERR_INVALID_UPDATE_TIMING);

	if (err != FSP_SUCCESS) {
		LOG_ERR("R_GLCDC_LayerChange failed (%d)", (int)err);
		return -EIO;
	}

	vid.back = 1;
	vid.frames = 0;
	vid.ready = true;

	LOG_INF("video: %ux%u x%u -> %ux%u CLUT8 at (%u,%u) on %ux%u panel", src_w, src_h, scale,
		vid.dst_w, vid.dst_h, (PANEL_W - vid.dst_w) / 2, (PANEL_H - vid.dst_h) / 2,
		(unsigned)PANEL_W, (unsigned)PANEL_H);
	LOG_INF("video: %u KiB surface + 2 x %u KiB scanout in SDRAM",
		(unsigned)(vid.src_stride * src_h / 1024),
		(unsigned)(vid.dst_stride * vid.dst_h / 1024));

	return 0;
}

uint8_t *plat_get_framebuffer(void)
{
	return surface;
}

unsigned plat_fb_stride(void)
{
	return vid.src_stride;
}

unsigned plat_fb_width(void)
{
	return vid.src_w;
}

unsigned plat_fb_height(void)
{
	return vid.src_h;
}

unsigned plat_scale(void)
{
	return vid.scale;
}

void plat_set_palette(const uint32_t *rgb888, unsigned start, unsigned count)
{
	/* The CLUT wants ARGB8888; the caller should not have to care. */
	static uint32_t argb[256];
	display_clut_cfg_t cfg;

	if (!vid.ready || start >= 256) {
		return;
	}

	count = MIN(count, 256 - start);

	for (unsigned i = 0; i < count; i++) {
		argb[i] = 0xFF000000u | (rgb888[i] & 0x00FFFFFFu);
	}

	cfg.p_base = argb;
	cfg.start = (uint16_t)start;
	cfg.size = (uint16_t)count;

	(void)R_GLCDC_ClutUpdate((display_ctrl_t *)vid.glcdc, &cfg, DISPLAY_FRAME_LAYER_1);
}

void plat_wait_vsync(void)
{
	while (vid.ready && flip_pending()) {
		k_yield();
	}
}

void plat_present(void)
{
	uint8_t *dst;
	fsp_err_t err;

	if (!vid.ready) {
		return;
	}

	dst = scanout[vid.back];

	if (vid.scale == 2) {
		blit_2x(surface, dst);
	} else {
		blit_nx(surface, dst);
	}

	/*
	 * The GLCDC is a bus master and does not see the D-cache. Without this
	 * the panel shows whatever made it out of the write buffer, which looks
	 * like intermittent block corruption rather than a blank screen.
	 */
	sys_cache_data_flush_range(dst, (size_t)vid.dst_stride * vid.dst_h);

	do {
		err = R_GLCDC_BufferChange((display_ctrl_t *)vid.glcdc, dst,
					   DISPLAY_FRAME_LAYER_1);
		if (err == FSP_ERR_INVALID_UPDATE_TIMING) {
			k_yield();
		}
	} while (err == FSP_ERR_INVALID_UPDATE_TIMING);

	vid.back ^= 1;
	vid.frames++;
}

uint32_t plat_frame_count(void)
{
	return vid.frames;
}
```

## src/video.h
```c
/*
 * video.h - the platform video interface.
 *
 * This header is deliberately portable: stdint/stdbool only, no Zephyr, no
 * FSP, no devicetree, no board constants. The machine layer includes this and
 * nothing else to get pixels onto a screen.
 *
 * The contract is:
 *
 *   - the machine renders its NATIVE raster (224x288 for a vertical arcade
 *     board) as 8-bit palette indices into the buffer plat_get_framebuffer()
 *     hands back;
 *   - plat_present() scales it, gets it to the display, and returns;
 *   - the machine never learns the panel size, the scale factor, the pixel
 *     format or how the flip happens.
 *
 * Scale and panel geometry are derived at runtime from devicetree inside the
 * implementation, not hardcoded here. A different panel, or a game with a
 * different raster, needs no change above this line.
 *
 * See notes/02-video.md for why the implementation looks the way it does.
 */

#ifndef ARCADE_VIDEO_H_
#define ARCADE_VIDEO_H_

#include <stdbool.h>
#include <stdint.h>

/*
 * Set up the display for a src_w x src_h 8bpp indexed raster. Picks the
 * largest integer scale that fits the panel and centres the result.
 *
 * Must run from a thread, after the display/MIPI-DSI/panel drivers have
 * initialised - not from an init hook.
 *
 * Returns 0, or negative errno. -ERANGE means the raster does not fit the
 * panel even at 1:1.
 */
int plat_video_init(unsigned src_w, unsigned src_h);

/*
 * The machine's drawing surface: src_w x src_h bytes of palette index, one
 * byte per pixel, plat_fb_stride() bytes per row. Stable for the lifetime of
 * the program - it does not flip, so the machine can keep a pointer and can
 * leave static background tiles in place between frames.
 */
uint8_t *plat_get_framebuffer(void);
unsigned plat_fb_stride(void);

/* Geometry, for callers that want to report or centre something. */
unsigned plat_fb_width(void);
unsigned plat_fb_height(void);
unsigned plat_scale(void);

/*
 * Load palette entries. Colours are 0x00RRGGBB (alpha is supplied by the
 * platform). Cheap, and safe to call while displaying: the hardware
 * double-buffers the palette and swaps it on the next vsync.
 */
void plat_set_palette(const uint32_t *rgb888, unsigned start, unsigned count);

/*
 * Block until the display is finished with the buffer we are about to draw
 * into. Call this at the top of a frame, before touching the framebuffer.
 */
void plat_wait_vsync(void);

/*
 * Scale the framebuffer to the display and show it. Returns as soon as the
 * flip is queued; the swap itself happens at the next vsync, so it is atomic
 * and cannot tear.
 */
void plat_present(void);

/* Frames presented since plat_video_init(). */
uint32_t plat_frame_count(void);

#endif /* ARCADE_VIDEO_H_ */
```
